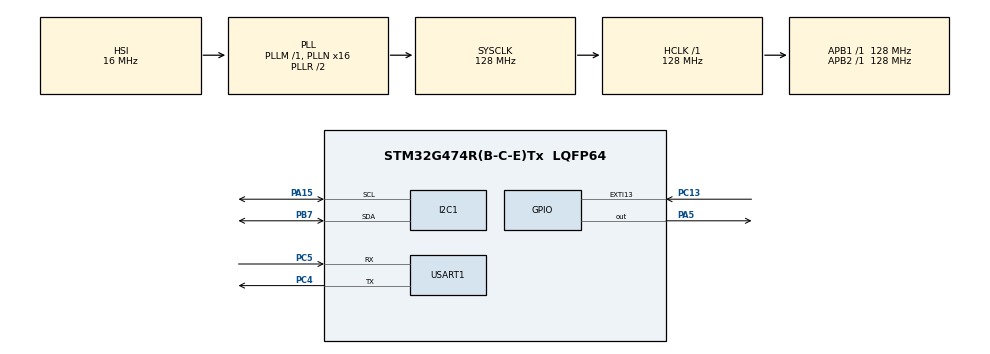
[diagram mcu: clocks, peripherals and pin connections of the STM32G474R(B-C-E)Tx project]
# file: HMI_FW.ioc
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I2C1.Timing=0x20E2A7F4
Mcu.Family=STM32G4
Mcu.Name=STM32G474R(B-C-E)Tx
Mcu.Package=LQFP64
NUCLEO-G474RE.BUTTON=1
NUCLEO-G474RE.LD2=true
NUCLEO-G474RE.VCP=true
NVIC.EXTI15_10_IRQn=true\:0\:0\:false\:false\:true\:true\:true\:true
NVIC.PriorityGroup=NVIC_PRIORITYGROUP_4
NVIC.USART1_IRQn=true\:0\:0\:false\:false\:true\:true\:true\:true
PA13.GPIO_Label=T_SWDIO
PA13.Signal=SYS_JTMS-SWDIO
PA14.GPIO_Label=T_SWCLK
PA14.Signal=SYS_JTCK-SWCLK
PA15.Mode=I2C
PA15.Signal=I2C1_SCL
PA2.Signal=LPUART1_TX
PA3.Signal=LPUART1_RX
PA5.Signal=GPIO_Output
PB3.GPIO_Label=T_SWO
PB3.Signal=SYS_JTDO-SWO
PB7.Mode=I2C
PB7.Signal=I2C1_SDA
PC13.Signal=GPXTI13
PC14-OSC32_IN.GPIO_Label=RCC_OSC32_IN
PC14-OSC32_IN.Signal=RCC_OSC32_IN
PC15-OSC32_OUT.GPIO_Label=RCC_OSC32_OUT
PC15-OSC32_OUT.Signal=RCC_OSC32_OUT
PC4.Mode=Asynchronous
PC4.Signal=USART1_TX
PC5.Mode=Asynchronous
PC5.Signal=USART1_RX
PF0-OSC_IN.GPIO_Label=RCC_OSC_IN
PF0-OSC_IN.Signal=RCC_OSC_IN
PF1-OSC_OUT.GPIO_Label=RCC_OSC_OUT
PF1-OSC_OUT.Signal=RCC_OSC_OUT
ProjectManager.HeapSize=0x200
ProjectManager.StackSize=0x400
ProjectManager.TargetToolchain=Makefile
RCC.ADC12Freq_Value=128000000
RCC.ADC345Freq_Value=128000000
RCC.AHBFreq_Value=128000000
RCC.APB1Freq_Value=128000000
RCC.APB1TimFreq_Value=128000000
RCC.APB2Freq_Value=128000000
RCC.APB2TimFreq_Value=128000000
RCC.CortexFreq_Value=128000000
RCC.EXTERNAL_CLOCK_VALUE=12288000
RCC.HCLKFreq_Value=128000000
RCC.HSE_VALUE=24000000
RCC.HSI48_VALUE=48000000
RCC.HSI_VALUE=16000000
RCC.LSE_VALUE=32768
RCC.PLLN=16
RCC.RTCClockSelection=RCC_RTCCLKSOURCE_LSE
RCC.SYSCLKFreq_VALUE=128000000
RCC.SYSCLKSource=RCC_SYSCLKSOURCE_PLLCLK
RCC.USBFreq_Value=128000000
RCC.VCOOutputFreq_Value=256000000
USART1.VirtualMode-Asynchronous=VM_ASYNC
VP_NUCLEO-G474RE_VS_BSP_COMMON.Mode=COMMON
VP_SYS_VS_DBSignals.Mode=DisableDeadBatterySignals
board=NUCLEO-G474RE

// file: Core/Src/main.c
/* USER CODE BEGIN Header */
/**
 ******************************************************************************
 * @file           : main.c
 * @brief          : Main program body
 ******************************************************************************
 * @attention
 *
 * Copyright (c) 2025 STMicroelectronics.
 * All rights reserved.
 *
 * This software is licensed under terms that can be found in the LICENSE file
 * in the root directory of this software component.
 * If no LICENSE file comes with this software, it is provided AS-IS.
 *
 ******************************************************************************
 */
/* USER CODE END Header */
#include "main.h"

COM_InitTypeDef BspCOMInit;
I2C_HandleTypeDef hi2c1;

UART_HandleTypeDef huart1;

void SystemClock_Config(void);
static void MX_GPIO_Init(void);
static void MX_I2C1_Init(void);
static void MX_USART1_UART_Init(void);

int main(void)
{

  /* MCU Configuration--------------------------------------------------------*/

  /* Reset of all peripherals, Initializes the Flash interface and the Systick. */
  HAL_Init();

  /* Configure the system clock */
  SystemClock_Config();

  /* Initialize all configured peripherals */
  MX_GPIO_Init();
  MX_I2C1_Init();
  MX_USART1_UART_Init();

  /* Initialize led */
  BSP_LED_Init(LED_GREEN);

  /* Initialize USER push-button, will be used to trigger an interrupt each time it's pressed.*/
  BSP_PB_Init(BUTTON_USER, BUTTON_MODE_EXTI);

  /* Initialize COM1 port (115200, 8 bits (7-bit data + 1 stop bit), no parity */
  BspCOMInit.BaudRate   = 115200;
  BspCOMInit.WordLength = COM_WORDLENGTH_8B;
  BspCOMInit.StopBits   = COM_STOPBITS_1;
  BspCOMInit.Parity     = COM_PARITY_NONE;
  BspCOMInit.HwFlowCtl  = COM_HWCONTROL_NONE;
  if (BSP_COM_Init(COM1, &BspCOMInit) != BSP_ERROR_NONE)
  {
    Error_Handler();
  }

  /* Infinite loop */
  /* USER CODE BEGIN WHILE */
  while (1)
  {

    BSP_LED_Toggle(LED_GREEN);
    HAL_Delay(100);
    /* USER CODE END WHILE */

  }
}

void SystemClock_Config(void)
{
  RCC_OscInitTypeDef RCC_OscInitStruct = {0};
  RCC_ClkInitTypeDef RCC_ClkInitStruct = {0};

  /** Configure the main internal regulator output voltage
  */
  HAL_PWREx_ControlVoltageScaling(PWR_REGULATOR_VOLTAGE_SCALE1);

  /** Initializes the RCC Oscillators according to the specified parameters
  * in the RCC_OscInitTypeDef structure.
  */
  RCC_OscInitStruct.OscillatorType = RCC_OSCILLATORTYPE_HSI;
  RCC_OscInitStruct.HSIState = RCC_HSI_ON;
  RCC_OscInitStruct.HSICalibrationValue = RCC_HSICALIBRATION_DEFAULT;
  RCC_OscInitStruct.PLL.PLLState = RCC_PLL_ON;
  RCC_OscInitStruct.PLL.PLLSource = RCC_PLLSOURCE_HSI;
  RCC_OscInitStruct.PLL.PLLM = RCC_PLLM_DIV1;
  RCC_OscInitStruct.PLL.PLLN = 16;
  RCC_OscInitStruct.PLL.PLLP = RCC_PLLP_DIV2;
  RCC_OscInitStruct.PLL.PLLQ = RCC_PLLQ_DIV2;
  RCC_OscInitStruct.PLL.PLLR = RCC_PLLR_DIV2;
  if (HAL_RCC_OscConfig(&RCC_OscInitStruct) != HAL_OK)
  {
    Error_Handler();
  }

  /** Initializes the CPU, AHB and APB buses clocks
  */
  RCC_ClkInitStruct.ClockType = RCC_CLOCKTYPE_HCLK|RCC_CLOCKTYPE_SYSCLK
                              |RCC_CLOCKTYPE_PCLK1|RCC_CLOCKTYPE_PCLK2;
  RCC_ClkInitStruct.SYSCLKSource = RCC_SYSCLKSOURCE_PLLCLK;
  RCC_ClkInitStruct.AHBCLKDivider = RCC_SYSCLK_DIV1;
  RCC_ClkInitStruct.APB1CLKDivider = RCC_HCLK_DIV1;
  RCC_ClkInitStruct.APB2CLKDivider = RCC_HCLK_DIV1;

  if (HAL_RCC_ClockConfig(&RCC_ClkInitStruct, FLASH_LATENCY_4) != HAL_OK)
  {
    Error_Handler();
  }
}

static void MX_I2C1_Init(void)
{

  hi2c1.Instance = I2C1;
  hi2c1.Init.Timing = 0x20E2A7F4;
  hi2c1.Init.OwnAddress1 = 0;
  hi2c1.Init.AddressingMode = I2C_ADDRESSINGMODE_7BIT;
  hi2c1.Init.DualAddressMode = I2C_DUALADDRESS_DISABLE;
  hi2c1.Init.OwnAddress2 = 0;
  hi2c1.Init.OwnAddress2Masks = I2C_OA2_NOMASK;
  hi2c1.Init.GeneralCallMode = I2C_GENERALCALL_DISABLE;
  hi2c1.Init.NoStretchMode = I2C_NOSTRETCH_DISABLE;
  if (HAL_I2C_Init(&hi2c1) != HAL_OK)
  {
    Error_Handler();
  }

  /** Configure Analogue filter
  */
  if (HAL_I2CEx_ConfigAnalogFilter(&hi2c1, I2C_ANALOGFILTER_ENABLE) != HAL_OK)
  {
    Error_Handler();
  }

  /** Configure Digital filter
  */
  if (HAL_I2CEx_ConfigDigitalFilter(&hi2c1, 0) != HAL_OK)
  {
    Error_Handler();
  }

}

static void MX_USART1_UART_Init(void)
{

  huart1.Instance = USART1;
  huart1.Init.BaudRate = 115200;
  huart1.Init.WordLength = UART_WORDLENGTH_8B;
  huart1.Init.StopBits = UART_STOPBITS_1;
  huart1.Init.Parity = UART_PARITY_NONE;
  huart1.Init.Mode = UART_MODE_TX_RX;
  huart1.Init.HwFlowCtl = UART_HWCONTROL_NONE;
  huart1.Init.OverSampling = UART_OVERSAMPLING_16;
  huart1.Init.OneBitSampling = UART_ONE_BIT_SAMPLE_DISABLE;
  huart1.Init.ClockPrescaler = UART_PRESCALER_DIV1;
  huart1.AdvancedInit.AdvFeatureInit = UART_ADVFEATURE_NO_INIT;
  if (HAL_UART_Init(&huart1) != HAL_OK)
  {
    Error_Handler();
  }
  if (HAL_UARTEx_SetTxFifoThreshold(&huart1, UART_TXFIFO_THRESHOLD_1_8) != HAL_OK)
  {
    Error_Handler();
  }
  if (HAL_UARTEx_SetRxFifoThreshold(&huart1, UART_RXFIFO_THRESHOLD_1_8) != HAL_OK)
  {
    Error_Handler();
  }
  if (HAL_UARTEx_DisableFifoMode(&huart1) != HAL_OK)
  {
    Error_Handler();
  }

}

static void MX_GPIO_Init(void)
{

  /* GPIO Ports Clock Enable */
  __HAL_RCC_GPIOC_CLK_ENABLE();
  __HAL_RCC_GPIOF_CLK_ENABLE();
  __HAL_RCC_GPIOA_CLK_ENABLE();
  __HAL_RCC_GPIOB_CLK_ENABLE();

}

void Error_Handler(void)
{
  __disable_irq();
  while (1)
  {
  }
}
